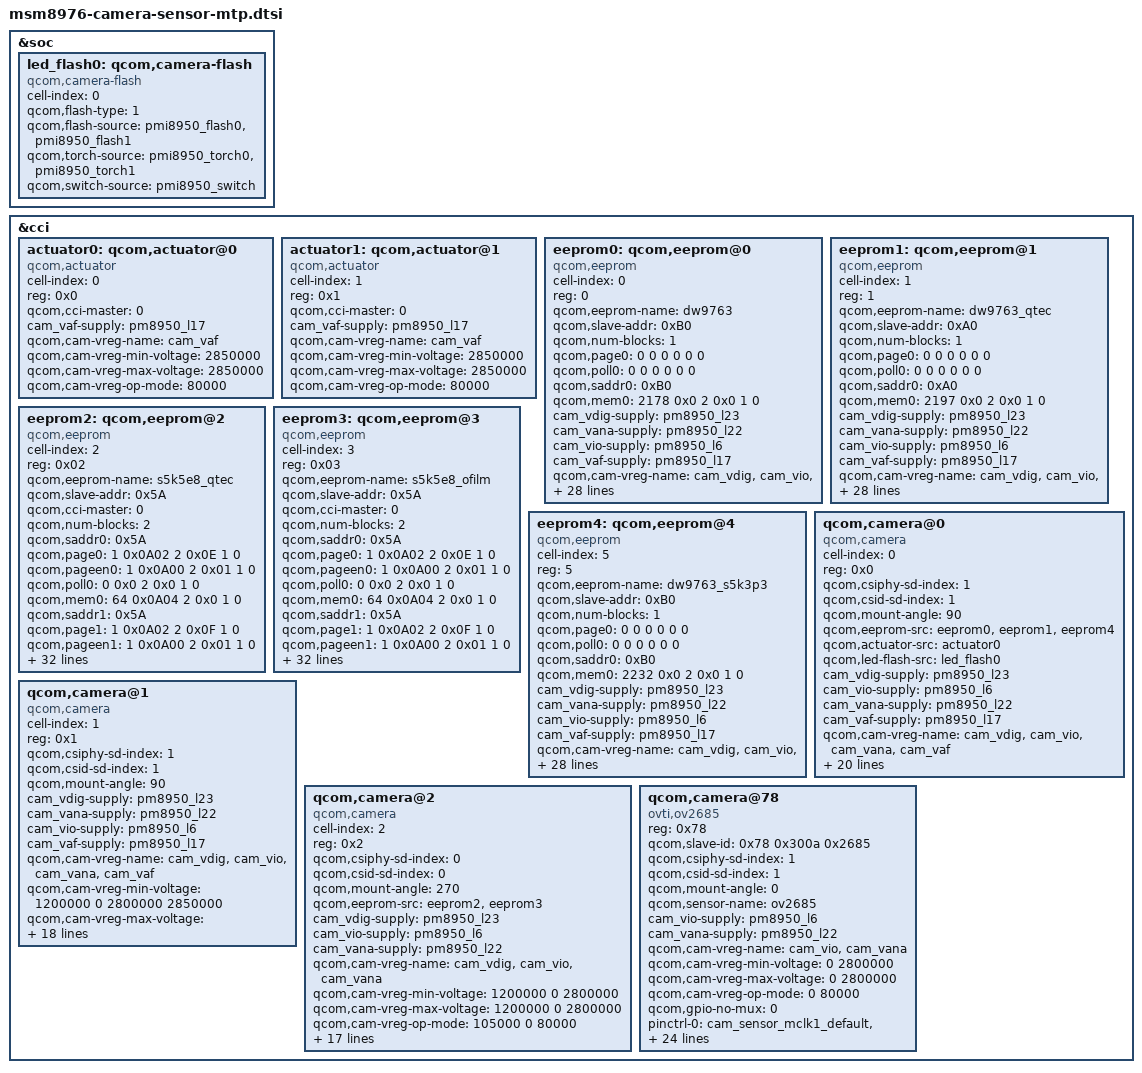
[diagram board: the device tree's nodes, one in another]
/*
 * Copyright (c) 2015-2016, The Linux Foundation. All rights reserved.
 * Copyright (C) 2016 XiaoMi, Inc.
 *
 * This program is free software; you can redistribute it and/or modify
 * it under the terms of the GNU General Public License version 2 and
 * only version 2 as published by the Free Software Foundation.
 *
 * This program is distributed in the hope that it will be useful,
 * but WITHOUT ANY WARRANTY; without even the implied warranty of
 * MERCHANTABILITY or FITNESS FOR A PARTICULAR PURPOSE.  See the
 * GNU General Public License for more details.
 */

&soc {
	led_flash0: qcom,camera-flash {
		cell-index = <0>;
		compatible = "qcom,camera-flash";
		qcom,flash-type = <1>;
		qcom,flash-source = <&pmi8950_flash0 &pmi8950_flash1>;
		qcom,torch-source = <&pmi8950_torch0 &pmi8950_torch1>;
		qcom,switch-source = <&pmi8950_switch>;
	};
};

&cci {
	actuator0: qcom,actuator@0 {
		cell-index = <0>;
		reg = <0x0>;
		compatible = "qcom,actuator";
		qcom,cci-master = <0>;
		cam_vaf-supply = <&pm8950_l17>;
		qcom,cam-vreg-name = "cam_vaf";
		qcom,cam-vreg-min-voltage = <2850000>;
		qcom,cam-vreg-max-voltage = <2850000>;
		qcom,cam-vreg-op-mode = <80000>;
	};

	actuator1: qcom,actuator@1 {
		cell-index = <1>;
		reg = <0x1>;
		compatible = "qcom,actuator";
		qcom,cci-master = <0>;
		cam_vaf-supply = <&pm8950_l17>;
		qcom,cam-vreg-name = "cam_vaf";
		qcom,cam-vreg-min-voltage = <2850000>;
		qcom,cam-vreg-max-voltage = <2850000>;
		qcom,cam-vreg-op-mode = <80000>;
	};

	eeprom0: qcom,eeprom@0 {
		cell-index = <0>;
		reg = <0>;
		qcom,eeprom-name = "dw9763";
		compatible = "qcom,eeprom";
		qcom,slave-addr = <0xB0>;
		qcom,num-blocks = <1>;
		qcom,page0 = <0 0 0 0 0 0>;
		qcom,poll0 = <0 0 0 0 0 0>;
		qcom,saddr0 = <0xB0>;
		qcom,mem0 = <2178 0x0 2 0x0 1 0>;

		cam_vdig-supply = <&pm8950_l23>;
		cam_vana-supply = <&pm8950_l22>;
		cam_vio-supply = <&pm8950_l6>;
		cam_vaf-supply = <&pm8950_l17>;
		qcom,cam-vreg-name = "cam_vdig", "cam_vio", "cam_vana", "cam_vaf";
		qcom,cam-vreg-min-voltage = <1200000 0 2950000 2850000>;
		qcom,cam-vreg-max-voltage = <1200000 0 2950000 2850000>;
		qcom,cam-vreg-op-mode = <105000 0 80000 100000>;
		qcom,gpio-no-mux = <0>;
		pinctrl-names = "cam_default", "cam_suspend";
		pinctrl-0 = <&cam_sensor_mclk2_default &cam_sensor_front1_default>;
		pinctrl-1 = <&cam_sensor_mclk2_sleep &cam_sensor_front1_sleep>;
		gpios = <&msm_gpio 28 0>,
			<&msm_gpio 131 0>;
		qcom,gpio-reset = <1>;
		qcom,gpio-req-tbl-num = <0 1>;
		qcom,gpio-req-tbl-flags = <1 0>;
		qcom,gpio-req-tbl-label = "CAMIF_MCLK2",
					  "CAM_RESET2";
		qcom,cam-power-seq-type = "sensor_vreg", "sensor_vreg", "sensor_vreg",
			"sensor_gpio", "sensor_gpio" , "sensor_clk";
		qcom,cam-power-seq-val = "cam_vdig", "cam_vana", "cam_vio",
			"sensor_gpio_reset", "sensor_gpio_standby","sensor_cam_mclk";
		qcom,cam-power-seq-cfg-val = <1 1 1 1 1 24000000>;
			qcom,cam-power-seq-delay = <1 1 1 30 30 5>;
		qcom,cci-master = <0>;
		status = "ok";
		clocks = <&clock_gcc clk_mclk2_clk_src>,
			<&clock_gcc clk_gcc_camss_mclk2_clk>;
		clock-names = "cam_src_clk", "cam_clk";
	};

	eeprom1: qcom,eeprom@1 {
		cell-index = <1>;
		reg = <1>;
		qcom,eeprom-name = "dw9763_qtec";
		compatible = "qcom,eeprom";
		qcom,slave-addr = <0xA0>;
		qcom,num-blocks = <1>;
		qcom,page0 = <0 0 0 0 0 0>;
		qcom,poll0 = <0 0 0 0 0 0>;
		qcom,saddr0 = <0xA0>;
		qcom,mem0 = <2197 0x0 2 0x0 1 0>;

		cam_vdig-supply = <&pm8950_l23>;
		cam_vana-supply = <&pm8950_l22>;
		cam_vio-supply = <&pm8950_l6>;
		cam_vaf-supply = <&pm8950_l17>;
		qcom,cam-vreg-name = "cam_vdig", "cam_vio", "cam_vana", "cam_vaf";
		qcom,cam-vreg-min-voltage = <1200000 0 2950000 2850000>;
		qcom,cam-vreg-max-voltage = <1200000 0 2950000 2850000>;
		qcom,cam-vreg-op-mode = <105000 0 80000 100000>;
		qcom,gpio-no-mux = <0>;
		pinctrl-names = "cam_default", "cam_suspend";
		pinctrl-0 = <&cam_sensor_mclk2_default &cam_sensor_front1_default>;
		pinctrl-1 = <&cam_sensor_mclk2_sleep &cam_sensor_front1_sleep>;
		gpios = <&msm_gpio 28 0>,
			<&msm_gpio 131 0>;
		qcom,gpio-reset = <1>;
		qcom,gpio-req-tbl-num = <0 1>;
		qcom,gpio-req-tbl-flags = <1 0>;
		qcom,gpio-req-tbl-label = "CAMIF_MCLK2",
					  "CAM_RESET2";
		qcom,cam-power-seq-type = "sensor_vreg", "sensor_vreg", "sensor_vreg",
			"sensor_gpio", "sensor_gpio" , "sensor_clk";
		qcom,cam-power-seq-val = "cam_vdig", "cam_vana", "cam_vio",
			"sensor_gpio_reset", "sensor_gpio_standby","sensor_cam_mclk";
		qcom,cam-power-seq-cfg-val = <1 1 1 1 1 24000000>;
			qcom,cam-power-seq-delay = <1 1 1 30 30 5>;
		qcom,cci-master = <0>;
		status = "ok";
		clocks = <&clock_gcc clk_mclk2_clk_src>,
			<&clock_gcc clk_gcc_camss_mclk2_clk>;
		clock-names = "cam_src_clk", "cam_clk";
	};

	eeprom2: qcom,eeprom@2 {
		cell-index = <2>;
		reg = <0x02>;
		qcom,eeprom-name = "s5k5e8_qtec";
		compatible = "qcom,eeprom";
		qcom,slave-addr = <0x5A>;
		qcom,cci-master = <0>;
		qcom,num-blocks = <2>;

	        qcom,saddr0 = <0x5A>;
		qcom,page0 = <1 0x0A02 2 0x0E 1 0>;
		qcom,pageen0 = <1 0x0A00 2 0x01 1 0>;
		qcom,poll0 = <0 0x0 2 0x0 1 0>;
		qcom,mem0 = <64 0x0A04 2 0x0 1 0>;

	        qcom,saddr1 = <0x5A>;
		qcom,page1 = <1 0x0A02 2 0x0F 1 0>;
		qcom,pageen1 = <1 0x0A00 2 0x01 1 0>;
		qcom,poll1 = <0 0x0 2 0x0 1 0>;
		qcom,mem1 = <6 0x0A04 2 0x0 1 0>;

		cam_vdig-supply = <&pm8950_l23>;
		cam_vio-supply = <&pm8950_l6>;
		cam_vana-supply = <&pm8950_l22>;
		qcom,cam-vreg-name = "cam_vdig", "cam_vio", "cam_vana";
		qcom,cam-vreg-min-voltage = <1200000 0 2800000>;
		qcom,cam-vreg-max-voltage = <1200000 0 2800000>;
		qcom,cam-vreg-op-mode = <105000 0 80000>;
		qcom,gpio-no-mux = <0>;
		pinctrl-names = "cam_default", "cam_suspend";
		pinctrl-0 = <&cam_sensor_mclk0_default &cam_sensor_front1_default>;
		pinctrl-1 = <&cam_sensor_mclk0_sleep &cam_sensor_front1_sleep>;
		gpios = <&msm_gpio 26 0>,
			<&msm_gpio 129 0>,
			<&msm_gpio 35 0>;
		qcom,gpio-reset = <1>;
		qcom,gpio-standby = <2>;
		qcom,gpio-req-tbl-num = <0 1 2>;
		qcom,gpio-req-tbl-flags = <1 0 0>;
		qcom,gpio-req-tbl-label = "CAMIF_MCLK0",
					  "CAM_RESET0",
					  "CAM_STANDBY0";
		qcom,cam-power-seq-type = "sensor_vreg", "sensor_vreg", "sensor_vreg",
			"sensor_gpio", "sensor_gpio" , "sensor_clk";
		qcom,cam-power-seq-val = "cam_vdig", "cam_vana", "cam_vio",
			"sensor_gpio_reset", "sensor_gpio_standby","sensor_cam_mclk";
		qcom,cam-power-seq-cfg-val = <1 1 1 1 1 24000000>;
		qcom,cam-power-seq-delay = <1 1 1 30 30 5>;
		status = "ok";
		clocks = <&clock_gcc clk_mclk0_clk_src>,
			<&clock_gcc clk_gcc_camss_mclk0_clk>;
		clock-names = "cam_src_clk", "cam_clk";
	};

	eeprom3: qcom,eeprom@3 {
		cell-index = <3>;
		reg = <0x03>;
		qcom,eeprom-name = "s5k5e8_ofilm";
		compatible = "qcom,eeprom";
		qcom,slave-addr = <0x5A>;
		qcom,cci-master = <0>;
		qcom,num-blocks = <2>;

	        qcom,saddr0 = <0x5A>;
		qcom,page0 = <1 0x0A02 2 0x0E 1 0>;
		qcom,pageen0 = <1 0x0A00 2 0x01 1 0>;
		qcom,poll0 = <0 0x0 2 0x0 1 0>;
		qcom,mem0 = <64 0x0A04 2 0x0 1 0>;

	        qcom,saddr1 = <0x5A>;
		qcom,page1 = <1 0x0A02 2 0x0F 1 0>;
		qcom,pageen1 = <1 0x0A00 2 0x01 1 0>;
		qcom,poll1 = <0 0x0 2 0x0 1 0>;
		qcom,mem1 = <6 0x0A04 2 0x0 1 0>;

		cam_vdig-supply = <&pm8950_l23>;
		cam_vio-supply = <&pm8950_l6>;
		cam_vana-supply = <&pm8950_l22>;
		qcom,cam-vreg-name = "cam_vdig", "cam_vio", "cam_vana";
		qcom,cam-vreg-min-voltage = <1200000 0 2800000>;
		qcom,cam-vreg-max-voltage = <1200000 0 2800000>;
		qcom,cam-vreg-op-mode = <105000 0 80000>;
		qcom,gpio-no-mux = <0>;
		pinctrl-names = "cam_default", "cam_suspend";
		pinctrl-0 = <&cam_sensor_mclk0_default &cam_sensor_front1_default>;
		pinctrl-1 = <&cam_sensor_mclk0_sleep &cam_sensor_front1_sleep>;
		gpios = <&msm_gpio 26 0>,
			<&msm_gpio 129 0>,
			<&msm_gpio 35 0>;
		qcom,gpio-reset = <1>;
		qcom,gpio-standby = <2>;
		qcom,gpio-req-tbl-num = <0 1 2>;
		qcom,gpio-req-tbl-flags = <1 0 0>;
		qcom,gpio-req-tbl-label = "CAMIF_MCLK0",
					  "CAM_RESET0",
					  "CAM_STANDBY0";
		qcom,cam-power-seq-type = "sensor_vreg", "sensor_vreg", "sensor_vreg",
			"sensor_gpio", "sensor_gpio" , "sensor_clk";
		qcom,cam-power-seq-val = "cam_vdig", "cam_vana", "cam_vio",
			"sensor_gpio_reset", "sensor_gpio_standby","sensor_cam_mclk";
		qcom,cam-power-seq-cfg-val = <1 1 1 1 1 24000000>;
		qcom,cam-power-seq-delay = <1 1 1 30 30 5>;
		status = "ok";
		clocks = <&clock_gcc clk_mclk0_clk_src>,
			<&clock_gcc clk_gcc_camss_mclk0_clk>;
		clock-names = "cam_src_clk", "cam_clk";
	};

	eeprom4: qcom,eeprom@4 {
		cell-index = <5>;
		reg = <5>;
		qcom,eeprom-name = "dw9763_s5k3p3";
		compatible = "qcom,eeprom";
		qcom,slave-addr = <0xB0>;
		qcom,num-blocks = <1>;
		qcom,page0 = <0 0 0 0 0 0>;
		qcom,poll0 = <0 0 0 0 0 0>;
		qcom,saddr0 = <0xB0>;
		qcom,mem0 = <2232 0x0 2 0x0 1 0>;

		cam_vdig-supply = <&pm8950_l23>;
		cam_vana-supply = <&pm8950_l22>;
		cam_vio-supply = <&pm8950_l6>;
		cam_vaf-supply = <&pm8950_l17>;
		qcom,cam-vreg-name = "cam_vdig", "cam_vio", "cam_vana", "cam_vaf";
		qcom,cam-vreg-min-voltage = <1200000 0 2950000 2850000>;
		qcom,cam-vreg-max-voltage = <1200000 0 2950000 2850000>;
		qcom,cam-vreg-op-mode = <105000 0 80000 100000>;
		qcom,gpio-no-mux = <0>;
		pinctrl-names = "cam_default", "cam_suspend";
		pinctrl-0 = <&cam_sensor_mclk2_default &cam_sensor_front1_default>;
		pinctrl-1 = <&cam_sensor_mclk2_sleep &cam_sensor_front1_sleep>;
		gpios = <&msm_gpio 28 0>,
			<&msm_gpio 131 0>;
		qcom,gpio-reset = <1>;
		qcom,gpio-req-tbl-num = <0 1>;
		qcom,gpio-req-tbl-flags = <1 0>;
		qcom,gpio-req-tbl-label = "CAMIF_MCLK2",
					  "CAM_RESET2";
		qcom,cam-power-seq-type = "sensor_vreg", "sensor_vreg", "sensor_vreg",
			"sensor_gpio", "sensor_gpio" , "sensor_clk";
		qcom,cam-power-seq-val = "cam_vdig", "cam_vana", "cam_vio",
			"sensor_gpio_reset", "sensor_gpio_standby","sensor_cam_mclk";
		qcom,cam-power-seq-cfg-val = <1 1 1 1 1 24000000>;
			qcom,cam-power-seq-delay = <1 1 1 30 30 5>;
		qcom,cci-master = <0>;
		status = "ok";
		clocks = <&clock_gcc clk_mclk2_clk_src>,
			<&clock_gcc clk_gcc_camss_mclk2_clk>;
		clock-names = "cam_src_clk", "cam_clk";
	};

	qcom,camera@0 {
		cell-index = <0>;
		compatible = "qcom,camera";
		reg = <0x0>;
		qcom,csiphy-sd-index = <1>;
		qcom,csid-sd-index = <1>;
		qcom,mount-angle = <90>;
		qcom,eeprom-src = <&eeprom0 &eeprom1 &eeprom4>;
		qcom,actuator-src = <&actuator0>;
		qcom,led-flash-src = <&led_flash0>;
		cam_vdig-supply = <&pm8950_l23>;
		cam_vio-supply = <&pm8950_l6>;
		cam_vana-supply = <&pm8950_l22>;
		cam_vaf-supply = <&pm8950_l17>;
		qcom,cam-vreg-name = "cam_vdig", "cam_vio", "cam_vana", "cam_vaf";
		qcom,cam-vreg-min-voltage = <1200000 0 2950000 2850000>;
		qcom,cam-vreg-max-voltage = <1200000 0 2950000 2850000>;
		qcom,cam-vreg-op-mode = <200000 0 80000 100000>;
		pinctrl-names = "cam_default", "cam_suspend";
		pinctrl-0 = <&cam_sensor_mclk2_default &cam_sensor_rear_default>;
		pinctrl-1 = <&cam_sensor_mclk2_sleep &cam_sensor_rear_sleep>;
		gpios = <&msm_gpio 28 0>,
			<&msm_gpio 131 0>;
		qcom,gpio-reset = <1>;
		qcom,gpio-req-tbl-num = <0 1>;
		qcom,gpio-req-tbl-flags = <1 0>;
		qcom,gpio-req-tbl-label = "CAMIF_MCLK2",
			"CAM_RESET2";
		qcom,sensor-position = <0>;
		qcom,sensor-mode = <0>;
		qcom,cci-master = <0>;
		status = "ok";
		clocks = <&clock_gcc clk_mclk2_clk_src>,
				<&clock_gcc clk_gcc_camss_mclk2_clk>;
		clock-names = "cam_src_clk", "cam_clk";
	};

	qcom,camera@1 {
		cell-index = <1>;
		compatible = "qcom,camera";
		reg = <0x1>;
		qcom,csiphy-sd-index = <1>;
		qcom,csid-sd-index = <1>;
		qcom,mount-angle = <90>;
		cam_vdig-supply = <&pm8950_l23>;
		cam_vana-supply = <&pm8950_l22>;
		cam_vio-supply = <&pm8950_l6>;
		cam_vaf-supply = <&pm8950_l17>;
		qcom,cam-vreg-name = "cam_vdig", "cam_vio", "cam_vana",
							"cam_vaf";
		qcom,cam-vreg-min-voltage = <1200000 0 2800000 2850000>;
		qcom,cam-vreg-max-voltage = <1200000 0 2800000 2850000>;
		qcom,cam-vreg-op-mode = <200000 0 80000 100000>;
		pinctrl-names = "cam_default", "cam_suspend";
		pinctrl-0 = <&cam_sensor_mclk1_default &cam_sensor_front_default>;
		pinctrl-1 = <&cam_sensor_mclk1_sleep &cam_sensor_front_sleep>;
		gpios = <&msm_gpio 27 0>,
			<&msm_gpio 130 0>,
			<&msm_gpio 36 0>;
		qcom,gpio-reset = <1>;
		qcom,gpio-standby = <2>;
		qcom,gpio-req-tbl-num = <0 1 2>;
		qcom,gpio-req-tbl-flags = <1 0 0>;
		qcom,gpio-req-tbl-label = "CAMIF_MCLK1",
			"CAM_RESET1",
			"CAM_STANDBY1";
		qcom,sensor-position = <1>;
		qcom,sensor-mode = <0>;
		qcom,cci-master = <0>;
		status = "ok";
		clocks = <&clock_gcc clk_mclk1_clk_src>,
				<&clock_gcc clk_gcc_camss_mclk1_clk>;
		clock-names = "cam_src_clk", "cam_clk";
	};

	qcom,camera@2 {
		cell-index = <2>;
		compatible = "qcom,camera";
		reg = <0x2>;
		qcom,csiphy-sd-index = <0>;
		qcom,csid-sd-index = <0>;
		qcom,mount-angle = <270>;
		qcom,eeprom-src = <&eeprom2 &eeprom3>;
		cam_vdig-supply = <&pm8950_l23>;
		cam_vio-supply = <&pm8950_l6>;
		cam_vana-supply = <&pm8950_l22>;
		qcom,cam-vreg-name = "cam_vdig", "cam_vio", "cam_vana";
		qcom,cam-vreg-min-voltage = <1200000 0 2800000>;
		qcom,cam-vreg-max-voltage = <1200000 0 2800000>;
		qcom,cam-vreg-op-mode = <105000 0 80000>;
		qcom,gpio-no-mux = <0>;
		pinctrl-names = "cam_default", "cam_suspend";
		pinctrl-0 = <&cam_sensor_mclk0_default &cam_sensor_front1_default>;
		pinctrl-1 = <&cam_sensor_mclk0_sleep &cam_sensor_front1_sleep>;
		gpios = <&msm_gpio 26 0>,
			<&msm_gpio 129 0>,
			<&msm_gpio 35 0>;
		qcom,gpio-reset = <1>;
		qcom,gpio-standby = <2>;
		qcom,gpio-req-tbl-num = <0 1 2>;
		qcom,gpio-req-tbl-flags = <1 0 0>;
		qcom,gpio-req-tbl-label = "CAMIF_MCLK0",
					  "CAM_RESET0",
					  "CAM_STANDBY0";
		qcom,sensor-position = <1>;
		qcom,sensor-mode = <0>;
		qcom,cci-master = <0>;
		status = "ok";
		clocks = <&clock_gcc clk_mclk0_clk_src>,
			<&clock_gcc clk_gcc_camss_mclk0_clk>;
		clock-names = "cam_src_clk", "cam_clk";
	};

	qcom,camera@78 {
		compatible = "ovti,ov2685";
		reg = <0x78>;
		qcom,slave-id = <0x78 0x300a 0x2685>;
		qcom,csiphy-sd-index = <1>;
		qcom,csid-sd-index = <1>;
		qcom,mount-angle = <0>;
		qcom,sensor-name = "ov2685";
		cam_vio-supply = <&pm8950_l6>;
		cam_vana-supply = <&pm8950_l22>;
		qcom,cam-vreg-name = "cam_vio", "cam_vana";
		qcom,cam-vreg-min-voltage = <0 2800000>;
		qcom,cam-vreg-max-voltage = <0 2800000>;
		qcom,cam-vreg-op-mode = <0 80000>;
		qcom,gpio-no-mux = <0>;
		pinctrl-names = "cam_default", "cam_suspend";
		pinctrl-0 = <&cam_sensor_mclk1_default &cam_sensor_front_default
				&cam_sensor_front_vdig>;
		pinctrl-1 = <&cam_sensor_mclk1_sleep &cam_sensor_front_sleep
				&cam_sensor_front_vdig_sleep>;
		gpios = <&msm_gpio 27 0>,
			<&msm_gpio 130 0>,
			<&msm_gpio 36 0>,
			<&msm_gpio 105 0>;
		qcom,gpio-reset = <1>;
		qcom,gpio-standby = <2>;
		qcom,gpio-vdig = <3>;
		qcom,gpio-req-tbl-num = <0 1 2 3>;
		qcom,gpio-req-tbl-flags = <1 0 0 0>;
		qcom,gpio-req-tbl-label = "CAMIF_MCLK1",
					  "CAM_RESET1",
					  "CAM_STANDBY1",
					  "CAM_VDIG";
		qcom,gpio-set-tbl-num = <1 1>;
		qcom,gpio-set-tbl-flags = <0 2>;
		qcom,gpio-set-tbl-delay = <1000 30000>;
		qcom,csi-lane-assign = <0x4320>;
		qcom,csi-lane-mask = <0x3>;
		qcom,sensor-position = <0x100>;
		qcom,sensor-mode = <1>;
		qcom,cci-master = <1>;
		status = "ok";
		clocks = <&clock_gcc clk_mclk1_clk_src>,
		<&clock_gcc clk_gcc_camss_mclk1_clk>;
		clock-names = "cam_src_clk", "cam_clk";
	};
};
